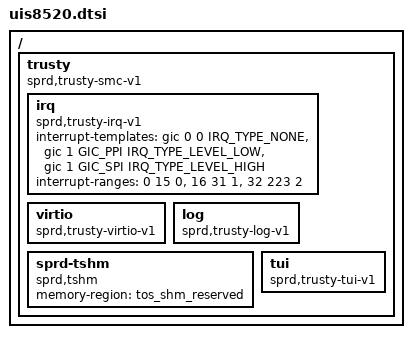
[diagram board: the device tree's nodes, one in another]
// SPDX-License-Identifier: GPL-2.0-only
/*
 * Spreadtrum sl8581e platform DTS file
 *
 * Copyright (C) 2018, Unisoc (Shanghai) Technologies Co., Ltd
 *
 * This file is licensed under a dual GPLv2 or X11 license.
 */

/ {
	trusty {
		compatible = "sprd,trusty-smc-v1";

		irq {
			compatible = "sprd,trusty-irq-v1";
			interrupt-templates = <&gic 0 0 IRQ_TYPE_NONE>,
					      <&gic 1 GIC_PPI IRQ_TYPE_LEVEL_LOW>,
					      <&gic 1 GIC_SPI IRQ_TYPE_LEVEL_HIGH>;
			interrupt-ranges = < 0  15 0>,
					   <16  31 1>,
					   <32 223 2>;
		};

		virtio {
			compatible = "sprd,trusty-virtio-v1";
		};

		log {
			compatible = "sprd,trusty-log-v1";
		};

		sprd-tshm {
			compatible = "sprd,tshm";
		/* "tos_shm_reserved" relies on "ums9620-common.dtsi" file, so you need to */
		/* include the file in this path -- "sprd/reserved-memory/ums9620-common.dtsi" */
			memory-region = <&tos_shm_reserved>;
		};

		tui {
			compatible = "sprd,trusty-tui-v1";
		};
	};
};
